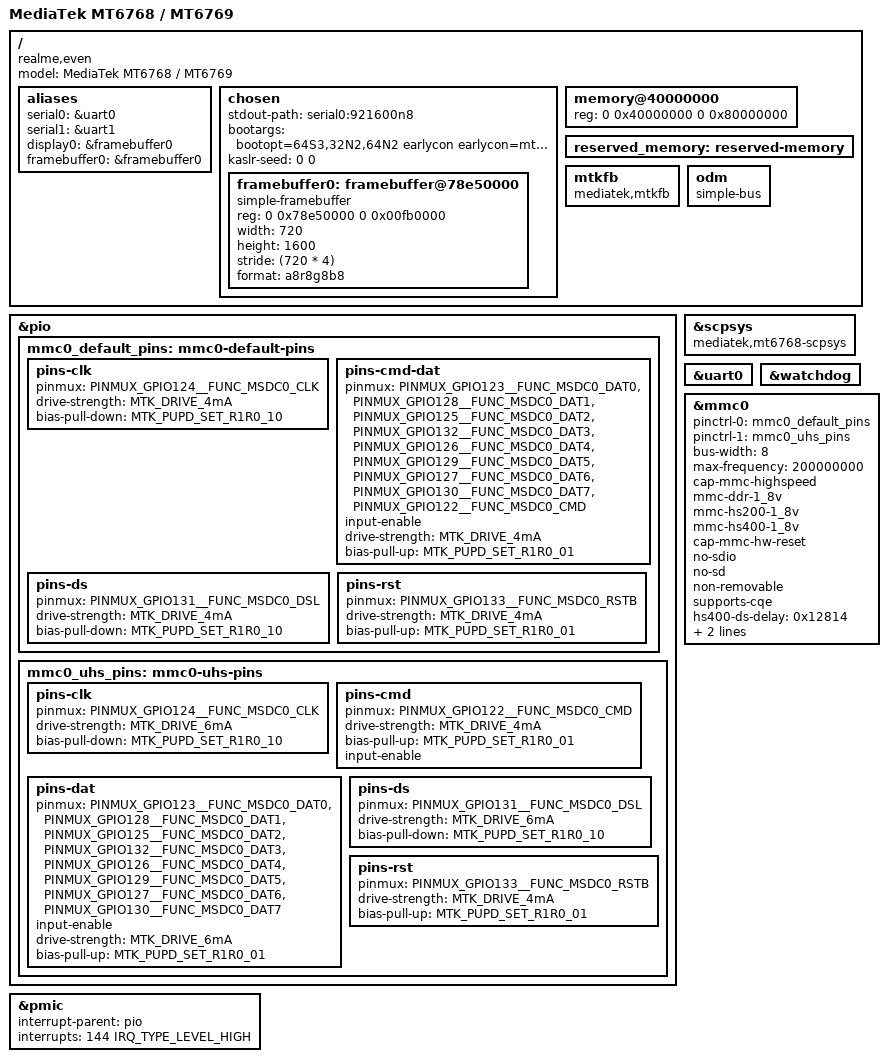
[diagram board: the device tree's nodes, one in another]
// SPDX-License-Identifier: GPL-2.0
/*
 * Copyright (C) 2026 Badmaneers <dukebraham24@gmail.com>
 *
 * Universal base device tree for MediaTek MT6768 / MT6769
 * Realme C25 / C25s / Narzo 50A (codename even, RMX3430 / RMX3193).
 */

/dts-v1/;

#include "mt6768.dtsi"
#include "mt6358.dtsi"
#include <dt-bindings/pinctrl/mt65xx.h>

/ {
	model = "MediaTek MT6768 / MT6769";
	compatible = "realme,even", "mediatek,mt6769", "mediatek,mt6768";

	aliases {
		serial0 = &uart0;
		serial1 = &uart1;
		display0 = &framebuffer0;
		framebuffer0 = &framebuffer0;
	};

	chosen: chosen {
		#address-cells = <2>;
		#size-cells = <2>;
		ranges;
		stdout-path = "serial0:921600n8";
		bootargs = "bootopt=64S3,32N2,64N2 earlycon earlycon=mtk8250,mmio32,0x11002000 keep_bootcon console=ttyS0,921600n8 console=tty0 clk_ignore_unused pd_ignore_unused regulator_ignore_unused androidboot.selinux=permissive selinux=1 enforcing=0 root=/dev/ram loop.max_part=7 ramoops.mem_address=0x4d010000 ramoops.mem_size=0x000e0000 ramoops.console_size=0x00040000 ramoops.record_size=0x00010000 ramoops.pmsg_size=0x00010000 ramoops.dump_oops=1";
		kaslr-seed = <0 0>;

		framebuffer0: framebuffer@78e50000 {
			compatible = "simple-framebuffer";
			reg = <0 0x78e50000 0 0x00fb0000>;
			width = <720>;
			height = <1600>;
			stride = <(720 * 4)>;
			format = "a8r8g8b8";
			status = "okay";
		};
	};

	memory@40000000 {
		device_type = "memory";
		reg = <0 0x40000000 0 0x80000000>;
	};

	reserved_memory: reserved-memory {
		#address-cells = <2>;
		#size-cells = <2>;
		ranges;
	};

	mtkfb: mtkfb {
		compatible = "mediatek,mtkfb";
	};

	odm: odm {
		compatible = "simple-bus";
	};
};

gpio: &pio {
};

&scpsys {
	compatible = "mediatek,mt6768-scpsys", "syscon", "simple-mfd", "mediatek,sleep";
};

&uart0 {
	status = "okay";
};

&watchdog {
	status = "okay";
};

&mmc0 {
	status = "okay";
	pinctrl-names = "default", "state_uhs";
	pinctrl-0 = <&mmc0_default_pins>;
	pinctrl-1 = <&mmc0_uhs_pins>;
	bus-width = <8>;
	max-frequency = <200000000>;
	cap-mmc-highspeed;
	mmc-ddr-1_8v;
	mmc-hs200-1_8v;
	mmc-hs400-1_8v;
	cap-mmc-hw-reset;
	no-sdio;
	no-sd;
	non-removable;
	supports-cqe;
	hs400-ds-delay = <0x12814>;
	vmmc-supply = <&mt6358_vemc_reg>;
	vqmmc-supply = <&mt6358_vio18_reg>;
};

&pmic {
	interrupt-parent = <&pio>;
	interrupts = <144 IRQ_TYPE_LEVEL_HIGH>;
};

&pio {
	mmc0_default_pins: mmc0-default-pins {
		pins-clk {
			pinmux = <PINMUX_GPIO124__FUNC_MSDC0_CLK>;
			drive-strength = <MTK_DRIVE_4mA>;
			bias-pull-down = <MTK_PUPD_SET_R1R0_10>;
		};

		pins-cmd-dat {
			pinmux = <PINMUX_GPIO123__FUNC_MSDC0_DAT0>,
				 <PINMUX_GPIO128__FUNC_MSDC0_DAT1>,
				 <PINMUX_GPIO125__FUNC_MSDC0_DAT2>,
				 <PINMUX_GPIO132__FUNC_MSDC0_DAT3>,
				 <PINMUX_GPIO126__FUNC_MSDC0_DAT4>,
				 <PINMUX_GPIO129__FUNC_MSDC0_DAT5>,
				 <PINMUX_GPIO127__FUNC_MSDC0_DAT6>,
				 <PINMUX_GPIO130__FUNC_MSDC0_DAT7>,
				 <PINMUX_GPIO122__FUNC_MSDC0_CMD>;
			input-enable;
			drive-strength = <MTK_DRIVE_4mA>;
			bias-pull-up = <MTK_PUPD_SET_R1R0_01>;
		};

		pins-ds {
			pinmux = <PINMUX_GPIO131__FUNC_MSDC0_DSL>;
			drive-strength = <MTK_DRIVE_4mA>;
			bias-pull-down = <MTK_PUPD_SET_R1R0_10>;
		};

		pins-rst {
			pinmux = <PINMUX_GPIO133__FUNC_MSDC0_RSTB>;
			drive-strength = <MTK_DRIVE_4mA>;
			bias-pull-up = <MTK_PUPD_SET_R1R0_01>;
		};
	};

	mmc0_uhs_pins: mmc0-uhs-pins {
		pins-clk {
			pinmux = <PINMUX_GPIO124__FUNC_MSDC0_CLK>;
			drive-strength = <MTK_DRIVE_6mA>;
			bias-pull-down = <MTK_PUPD_SET_R1R0_10>;
		};

		pins-cmd {
			pinmux = <PINMUX_GPIO122__FUNC_MSDC0_CMD>;
			drive-strength = <MTK_DRIVE_4mA>;
			bias-pull-up = <MTK_PUPD_SET_R1R0_01>;
			input-enable;
		};

		pins-dat {
			pinmux = <PINMUX_GPIO123__FUNC_MSDC0_DAT0>,
				 <PINMUX_GPIO128__FUNC_MSDC0_DAT1>,
				 <PINMUX_GPIO125__FUNC_MSDC0_DAT2>,
				 <PINMUX_GPIO132__FUNC_MSDC0_DAT3>,
				 <PINMUX_GPIO126__FUNC_MSDC0_DAT4>,
				 <PINMUX_GPIO129__FUNC_MSDC0_DAT5>,
				 <PINMUX_GPIO127__FUNC_MSDC0_DAT6>,
				 <PINMUX_GPIO130__FUNC_MSDC0_DAT7>;
			input-enable;
			drive-strength = <MTK_DRIVE_6mA>;
			bias-pull-up = <MTK_PUPD_SET_R1R0_01>;
		};

		pins-ds {
			pinmux = <PINMUX_GPIO131__FUNC_MSDC0_DSL>;
			drive-strength = <MTK_DRIVE_6mA>;
			bias-pull-down = <MTK_PUPD_SET_R1R0_10>;
		};

		pins-rst {
			pinmux = <PINMUX_GPIO133__FUNC_MSDC0_RSTB>;
			drive-strength = <MTK_DRIVE_4mA>;
			bias-pull-up = <MTK_PUPD_SET_R1R0_01>;
		};
	};
};
